AUTOSAR XML (schema 00048)
package /MICROSAR/AdcIf/ComponentTypes
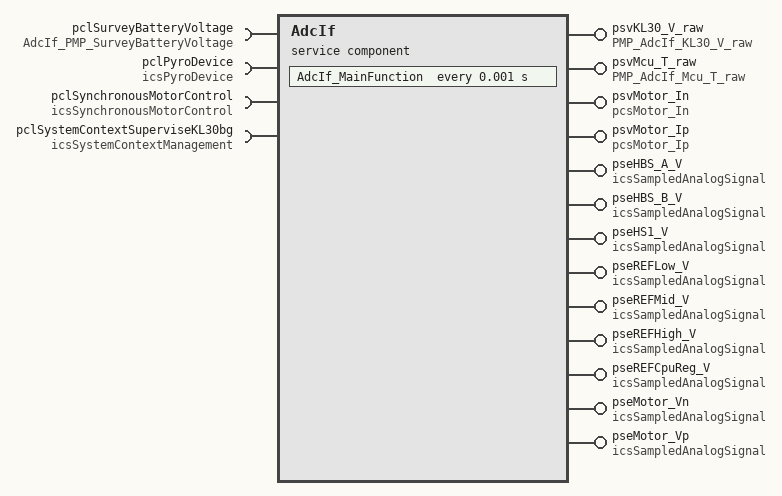
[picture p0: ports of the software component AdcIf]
  service sw component type AdcIf
    require port pclSurveyBatteryVoltage: client-com-spec=Monitor, required-interface=AdcIf_PMP_SurveyBatteryVoltage
    13 x provide port:
      psvKL30_V_raw: provided-interface=PMP_AdcIf_KL30_V_raw
        provided-com-specs:
          operation=Get_100ms, queue-length=1
          operation=Get, queue-length=1
          operation=Get_10ms, queue-length=1
          operation=Get_20ms, queue-length=1
      psvMcu_T_raw: server-com-spec{operation=Get_10ms, queue-length=1}, provided-interface=PMP_AdcIf_Mcu_T_raw
      psvMotor_In: provided-com-specs=[{operation=raw_Get_10ms, queue-length=1}, {operation=raw_Get, queue-length=1}], provided-interface=pcsMotor_In
      psvMotor_Ip: provided-com-specs=[{operation=raw_Get_10ms, queue-length=1}, {operation=raw_Get, queue-length=1}], provided-interface=pcsMotor_Ip
      pseHBS_A_V: provided-interface=icsSampledAnalogSignal
        provided-com-specs:
          operation=Get_2ms, queue-length=1
          operation=Get_20ms, queue-length=1
          operation=Get_10ms, queue-length=1
          operation=Get_100ms, queue-length=1
          operation=Get, queue-length=1
      pseHBS_B_V: provided-interface=icsSampledAnalogSignal
        provided-com-specs:
          operation=Get_2ms, queue-length=1
          operation=Get_20ms, queue-length=1
          operation=Get_10ms, queue-length=1
          operation=Get_100ms, queue-length=1
          operation=Get, queue-length=1
      pseHS1_V: provided-interface=icsSampledAnalogSignal
        provided-com-specs:
          operation=Get_2ms, queue-length=1
          operation=Get_20ms, queue-length=1
          operation=Get_10ms, queue-length=1
          operation=Get_100ms, queue-length=1
          operation=Get, queue-length=1
      pseREFLow_V: provided-interface=icsSampledAnalogSignal
        provided-com-specs:
          operation=Get_2ms, queue-length=1
          operation=Get_20ms, queue-length=1
          operation=Get_10ms, queue-length=1
          operation=Get_100ms, queue-length=1
          operation=Get, queue-length=1
      pseREFMid_V: provided-interface=icsSampledAnalogSignal
        provided-com-specs:
          operation=Get_2ms, queue-length=1
          operation=Get_20ms, queue-length=1
          operation=Get_10ms, queue-length=1
          operation=Get_100ms, queue-length=1
          operation=Get, queue-length=1
      pseREFHigh_V: provided-interface=icsSampledAnalogSignal
        provided-com-specs:
          operation=Get_2ms, queue-length=1
          operation=Get_20ms, queue-length=1
          operation=Get_10ms, queue-length=1
          operation=Get_100ms, queue-length=1
          operation=Get, queue-length=1
      pseREFCpuReg_V: provided-interface=icsSampledAnalogSignal
        provided-com-specs:
          operation=Get_2ms, queue-length=1
          operation=Get_20ms, queue-length=1
          operation=Get_10ms, queue-length=1
          operation=Get_100ms, queue-length=1
          operation=Get, queue-length=1
      pseMotor_Vn: provided-interface=icsSampledAnalogSignal
        provided-com-specs:
          operation=Get_2ms, queue-length=1
          operation=Get_20ms, queue-length=1
          operation=Get_10ms, queue-length=1
          operation=Get_100ms, queue-length=1
          operation=Get, queue-length=1
      pseMotor_Vp: provided-interface=icsSampledAnalogSignal
        provided-com-specs:
          operation=Get_2ms, queue-length=1
          operation=Get_20ms, queue-length=1
          operation=Get_10ms, queue-length=1
          operation=Get_100ms, queue-length=1
          operation=Get, queue-length=1
    require port pclPyroDevice: client-com-spec=GetPyroActivationStatus, required-interface=icsPyroDevice
    require port pclSynchronousMotorControl: required-com-specs=[ResetMotorStageStatus, ExecuteHighPowerStep, ExecuteEmergencyBrakingSequence], required-interface=icsSynchronousMotorControl
    require port pclSystemContextSuperviseKL30bg: required-interface=icsSystemContextManagement
      required-com-specs:
        SuperviseKL30bg
        RestoreSystemContext
        ManageSystemContextStorage
        GetMonitoredCycle
        GetLastTensionningState
        GetBatteryHysteresisThrs
    behavior AdcIf_InternalBehavior: data-type-mapping=DataTypeMappingSet_PP4G
      timing event TMT_AdcIf_MainFunction: start-on-event=AdcIf_MainFunction, period=0.001
      32 x operation invoked event:
        OIT_psvKL30_V_raw_Get_100ms_psvKL30_V_raw_Get_100ms: start-on-event=AdcIf_runGetKL30_V_100ms, operation=psvKL30_V_raw.Get_100ms
        OIT_psvKL30_V_raw_Get_psvKL30_V_raw_Get: start-on-event=AdcIf_runGetKL30_V, operation=psvKL30_V_raw.Get
        OIT_psvMcu_T_raw_Get_10ms_psvMcu_T_raw_Get_10ms: start-on-event=AdcIf_runGetMcu_T_10ms, operation=psvMcu_T_raw.Get_10ms
        OIT_psvMotor_Ip_raw_Get_10ms_psvMotor_Ip_raw_Get_10ms: start-on-event=AdcIf_runGetMotor_Ip_10ms, operation=psvMotor_Ip.raw_Get_10ms
        OIT_psvMotor_Ip_raw_Get_psvMotor_Ip_raw_Get: start-on-event=AdcIf_runGetMotor_Ip, operation=psvMotor_Ip.raw_Get
        OIT_psvMotor_In_raw_Get_10ms_psvMotor_In_raw_Get_10ms: start-on-event=AdcIf_runGetMotor_In_10ms, operation=psvMotor_In.raw_Get_10ms
        OIT_psvMotor_In_raw_Get_psvMotor_In_raw_Get: start-on-event=AdcIf_runGetMotor_In, operation=psvMotor_In.raw_Get
        OIT_psvKL30_V_raw_Get_10ms_psvKL30_V_raw_Get_10ms: start-on-event=AdcIf_runGetKL30_V_10ms, operation=psvKL30_V_raw.Get_10ms
        OIT_AdcIf_runGetHBS_A_V_pseHBS_A_V_Get: start-on-event=AdcIf_runGetHBS_A_V, operation=pseHBS_A_V.Get
        OIT_AdcIf_runGetHBS_B_V_pseHBS_B_V_Get: start-on-event=AdcIf_runGetHBS_B_V, operation=pseHBS_B_V.Get
        OIT_AdcIf_runGetHS1_V_pseHS1_V_Get: start-on-event=AdcIf_runGetHS1_V, operation=pseHS1_V.Get
        OIT_AdcIf_runGetHS1_V_10ms_pseHS1_V_Get_10ms: start-on-event=AdcIf_runGetHS1_V_10ms, operation=pseHS1_V.Get_10ms
        OIT_AdcIf_runGetHS1_V_20ms_pseHS1_V_Get_20ms: start-on-event=AdcIf_runGetHS1_V_20ms, operation=pseHS1_V.Get_20ms
        OIT_AdcIf_runGetHS1_V_100ms_pseHS1_V_Get_100ms: start-on-event=AdcIf_runGetHS1_V_100ms, operation=pseHS1_V.Get_100ms
        OIT_AdcIf_runGetHBS_A_V_10ms_pseHBS_A_V_Get_10ms: start-on-event=AdcIf_runGetHBS_A_V_10ms, operation=pseHBS_A_V.Get_10ms
        OIT_AdcIf_runGetHBS_A_V_20ms_pseHBS_A_V_Get_100ms: start-on-event=AdcIf_runGetHBS_A_V_100ms, operation=pseHBS_A_V.Get_100ms
        OIT_AdcIf_runGetHBS_B_V_10ms_pseHBS_B_V_Get_10ms: start-on-event=AdcIf_runGetHBS_B_V_10ms, operation=pseHBS_B_V.Get_10ms
        OIT_AdcIf_runGetHBS_B_V_100ms_pseHBS_B_V_Get_100ms: start-on-event=AdcIf_runGetHBS_B_V_100ms, operation=pseHBS_B_V.Get_100ms
        OIT_AdcIf_runGetRefLow_V_pseREFLow_V_Get: start-on-event=AdcIf_runGetRefLow_V, operation=pseREFLow_V.Get
        OIT_AdcIf_runGetRefLow_V_10ms_pseREFLow_V_Get_10ms: start-on-event=AdcIf_runGetRefLow_V_10ms, operation=pseREFLow_V.Get_10ms
        OIT_AdcIf_runGetRefLow_V_100ms_pseREFLow_V_Get_100ms: start-on-event=AdcIf_runGetRefLow_V_100ms, operation=pseREFLow_V.Get_100ms
        OIT_AdcIf_runGetRefCpuReg_V_pseREFCpuReg_V_Get: start-on-event=AdcIf_runGetRefCpuReg_V, operation=pseREFCpuReg_V.Get
        OIT_AdcIf_runGetRefMid_V_pseREFMid_V_Get: start-on-event=AdcIf_runGetRefMid_V, operation=pseREFMid_V.Get
        OIT_AdcIf_runGetRefHigh_V_pseREFHigh_V_Get: start-on-event=AdcIf_runGetRefHigh_V, operation=pseREFHigh_V.Get
        OIT_AdcIf_runGetMotor_Vp_pseMotor_Vp_Get: start-on-event=AdcIf_runGetMotor_Vp, operation=pseMotor_Vp.Get
        OIT_AdcIf_runGetMotor_Vn_pseMotor_Vn_Get: start-on-event=AdcIf_runGetMotor_Vn, operation=pseMotor_Vn.Get
        OIT_AdcIf_runGetKL30_V_20ms_psvKL30_V_raw_Get_20ms: start-on-event=AdcIf_runGetKL30_V_20ms, operation=psvKL30_V_raw.Get_20ms
        OIT_AdcIf_runGetMotor_Vn_20ms_pseMotor_Vn_Get_20ms: start-on-event=AdcIf_runGetMotor_Vn_20ms, operation=pseMotor_Vn.Get_20ms
        OIT_AdcIf_runGetMotor_Vn_100ms_pseMotor_Vn_Get_100ms: start-on-event=AdcIf_runGetMotor_Vn_100ms, operation=pseMotor_Vn.Get_100ms
        OIT_AdcIf_runGetMotor_Vp_20ms_pseMotor_Vp_Get_20ms: start-on-event=AdcIf_runGetMotor_Vp_20ms, operation=pseMotor_Vp.Get_20ms
        OIT_AdcIf_runGetMotor_Vp_100ms_pseMotor_Vp_Get_100ms: start-on-event=AdcIf_runGetMotor_Vp_100ms, operation=pseMotor_Vp.Get_100ms
        OIT_AdcIf_runGetKL30_V_2ms_psvKL30_V_raw_Get_2ms: start-on-event=AdcIf_runGetKL30_V_2ms, operation=psvKL30_V_raw.Get_2ms
      33 x runnable:
        AdcIf_MainFunction
          6 x sync call:
            SC_pclSurveyBatteryVoltage_Monitor: operation=pclSurveyBatteryVoltage.Monitor
            SC_icsPyroDevice_GetPyroActivationStatus: operation=pclPyroDevice.GetPyroActivationStatus
            SC_icsSynchronousMotorControl_ExecuteEmergencyBrakingSequence: operation=pclSynchronousMotorControl.ExecuteEmergencyBrakingSequence
            SC_icsSynchronousMotorControl_ExecuteHighPowerStep: operation=pclSynchronousMotorControl.ExecuteHighPowerStep
            SC_icsSynchronousMotorControl_ResetMotorStageStatus: operation=pclSynchronousMotorControl.ResetMotorStageStatus
            SC_pclSystemContextSuperviseKL30bg_SuperviseKL30bg: operation=pclSystemContextSuperviseKL30bg.SuperviseKL30bg
        AdcIf_runGetKL30_V_100ms
        AdcIf_runGetKL30_V: can-be-invoked-concurrently=true
        AdcIf_runGetMcu_T_10ms
        AdcIf_runGetMotor_Ip_10ms: can-be-invoked-concurrently=true
        AdcIf_runGetMotor_Ip: can-be-invoked-concurrently=true
        AdcIf_runGetMotor_In_10ms: can-be-invoked-concurrently=true
        AdcIf_runGetMotor_In: can-be-invoked-concurrently=true
        AdcIf_runGetKL30_V_10ms: can-be-invoked-concurrently=true
        AdcIf_runGetHBS_A_V: can-be-invoked-concurrently=true
        AdcIf_runGetHBS_B_V: can-be-invoked-concurrently=true
        AdcIf_runGetHS1_V: can-be-invoked-concurrently=true
        AdcIf_runGetHS1_V_10ms: can-be-invoked-concurrently=true
        AdcIf_runGetHS1_V_20ms: can-be-invoked-concurrently=true
        AdcIf_runGetHS1_V_100ms: can-be-invoked-concurrently=true
        AdcIf_runGetHBS_A_V_10ms: can-be-invoked-concurrently=true
        AdcIf_runGetHBS_A_V_100ms: can-be-invoked-concurrently=true
        AdcIf_runGetHBS_B_V_10ms: can-be-invoked-concurrently=true
        AdcIf_runGetHBS_B_V_100ms: can-be-invoked-concurrently=true
        AdcIf_runGetRefLow_V: can-be-invoked-concurrently=true
        AdcIf_runGetRefLow_V_10ms: can-be-invoked-concurrently=true
        AdcIf_runGetRefLow_V_100ms: can-be-invoked-concurrently=true
        AdcIf_runGetRefCpuReg_V: can-be-invoked-concurrently=true
        AdcIf_runGetRefMid_V: can-be-invoked-concurrently=true
        AdcIf_runGetRefHigh_V: can-be-invoked-concurrently=true
        AdcIf_runGetMotor_Vp: can-be-invoked-concurrently=true
        AdcIf_runGetMotor_Vn: can-be-invoked-concurrently=true
        AdcIf_runGetKL30_V_20ms: can-be-invoked-concurrently=true
        AdcIf_runGetMotor_Vn_20ms: can-be-invoked-concurrently=true
        AdcIf_runGetMotor_Vn_100ms: can-be-invoked-concurrently=true
        AdcIf_runGetMotor_Vp_20ms: can-be-invoked-concurrently=true
        AdcIf_runGetMotor_Vp_100ms: can-be-invoked-concurrently=true
        AdcIf_runGetKL30_V_2ms: can-be-invoked-concurrently=true
  swc implementation AdcIf_Implementation: behavior=AdcIf_InternalBehavior
